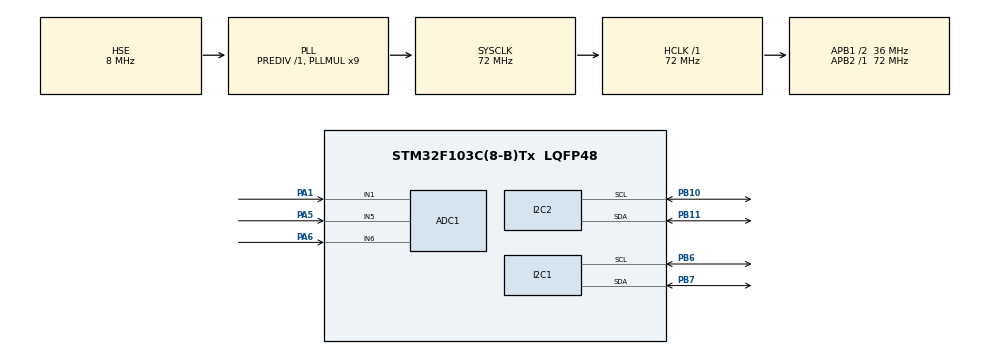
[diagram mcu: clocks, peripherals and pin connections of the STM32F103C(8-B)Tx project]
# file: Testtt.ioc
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ADC1.Channel-4\#ChannelRegularConversion=ADC_CHANNEL_1
ADC1.Channel-5\#ChannelRegularConversion=ADC_CHANNEL_5
ADC1.Channel-6\#ChannelRegularConversion=ADC_CHANNEL_6
ADC1.ContinuousConvMode=ENABLE
ADC1.NbrOfConversion=3
ADC1.NbrOfConversionFlag=1
ADC1.Rank-4\#ChannelRegularConversion=1
ADC1.Rank-5\#ChannelRegularConversion=2
ADC1.Rank-6\#ChannelRegularConversion=3
ADC1.SamplingTime-4\#ChannelRegularConversion=ADC_SAMPLETIME_239CYCLES_5
ADC1.SamplingTime-5\#ChannelRegularConversion=ADC_SAMPLETIME_239CYCLES_5
ADC1.SamplingTime-6\#ChannelRegularConversion=ADC_SAMPLETIME_239CYCLES_5
ADC1.master=1
Dma.ADC1.0.Direction=DMA_PERIPH_TO_MEMORY
Dma.ADC1.0.Instance=DMA1_Channel1
Dma.ADC1.0.MemDataAlignment=DMA_MDATAALIGN_HALFWORD
Dma.ADC1.0.MemInc=DMA_MINC_ENABLE
Dma.ADC1.0.Mode=DMA_CIRCULAR
Dma.ADC1.0.PeriphDataAlignment=DMA_PDATAALIGN_HALFWORD
Dma.ADC1.0.PeriphInc=DMA_PINC_DISABLE
Dma.ADC1.0.Priority=DMA_PRIORITY_LOW
Dma.Request0=ADC1
Mcu.Family=STM32F1
Mcu.Name=STM32F103C(8-B)Tx
Mcu.Package=LQFP48
NVIC.ADC1_2_IRQn=true\:0\:0\:false\:false\:true\:true\:true
NVIC.DMA1_Channel1_IRQn=true\:0\:0\:false\:false\:true\:false\:true
NVIC.I2C1_EV_IRQn=true\:0\:0\:false\:false\:true\:true\:true
NVIC.I2C2_EV_IRQn=true\:0\:0\:false\:false\:true\:true\:true
NVIC.PriorityGroup=NVIC_PRIORITYGROUP_4
NVIC.TIM3_IRQn=true\:0\:0\:false\:false\:true\:true\:true
PA1.Signal=ADCx_IN1
PA13.Mode=Serial_Wire
PA13.Signal=SYS_JTMS-SWDIO
PA14.Mode=Serial_Wire
PA14.Signal=SYS_JTCK-SWCLK
PA5.Signal=ADCx_IN5
PA6.Signal=ADCx_IN6
PB10.Mode=I2C
PB10.Signal=I2C2_SCL
PB11.Mode=I2C
PB11.Signal=I2C2_SDA
PB6.Mode=I2C
PB6.Signal=I2C1_SCL
PB7.Mode=I2C
PB7.Signal=I2C1_SDA
PD0-OSC_IN.Mode=HSE-External-Oscillator
PD0-OSC_IN.Signal=RCC_OSC_IN
PD1-OSC_OUT.Mode=HSE-External-Oscillator
PD1-OSC_OUT.Signal=RCC_OSC_OUT
ProjectManager.HeapSize=0x200
ProjectManager.StackSize=0x400
ProjectManager.TargetToolchain=MDK-ARM V5
RCC.ADCPresc=RCC_ADCPCLK2_DIV6
RCC.AHBFreq_Value=72000000
RCC.APB1CLKDivider=RCC_HCLK_DIV2
RCC.APB1Freq_Value=36000000
RCC.APB1TimFreq_Value=72000000
RCC.APB2Freq_Value=72000000
RCC.APB2TimFreq_Value=72000000
RCC.HCLKFreq_Value=72000000
RCC.PLLMUL=RCC_PLL_MUL9
RCC.PLLSourceVirtual=RCC_PLLSOURCE_HSE
RCC.SYSCLKFreq_VALUE=72000000
RCC.SYSCLKSource=RCC_SYSCLKSOURCE_PLLCLK
RCC.USBFreq_Value=72000000
SH.ADCx_IN1.0=ADC1_IN1,IN1
SH.ADCx_IN5.0=ADC1_IN5,IN5
SH.ADCx_IN6.0=ADC1_IN6,IN6
TIM3.Period=999
TIM3.Prescaler=71
VP_TIM3_VS_ClockSourceINT.Mode=Internal
board=custom

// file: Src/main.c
/* USER CODE BEGIN Header */
/**
  ******************************************************************************
  * @file           : main.c
  * @brief          : Main program body
  ******************************************************************************
  * @attention
  *
  * <h2><center>&copy; Copyright (c) 2020 STMicroelectronics.
  * All rights reserved.</center></h2>
  *
  * This software component is licensed by ST under BSD 3-Clause license,
  * the "License"; You may not use this file except in compliance with the
  * License. You may obtain a copy of the License at:
  *                        opensource.org/licenses/BSD-3-Clause
  *
  ******************************************************************************
  */
/* USER CODE END Header */
#include "main.h"

/* USER CODE BEGIN Includes */
#include "global_define.h"
#include "board.h"
#include "charger_system.h"
/* USER CODE END Includes */

/* USER CODE BEGIN PTD */
  uint32_t haha=0;
uint16_t adcVal[3];
uint16_t _dac_input;
uint8_t pd8_gpio;
Measure_value value;
float current;
/* USER CODE END PTD */

ADC_HandleTypeDef hadc1;
DMA_HandleTypeDef hdma_adc1;

I2C_HandleTypeDef hi2c1;
I2C_HandleTypeDef hi2c2;

TIM_HandleTypeDef htim3;

/* USER CODE BEGIN PV */
float adc_value_1;
float adc_value_2;
float current;
float write_DAC_1( float value)
{
	uint16_t address= 0x60<<1;
	uint8_t data[3];
  data[0]=64;
	uint16_t value_dac= (uint16_t)((value*4095.0f)/3.30f);
	data[1]=value_dac>>4;
	data[2]=value_dac<<4;

	HAL_I2C_Master_Transmit(&hi2c1,address,data,3,500);
	return value;
	}
float write_DAC_2( float value)
{
	uint16_t address= 0x61;
	uint8_t data[3];
  data[0]=64;
	uint16_t value_dac= (uint16_t)((value*4095.0f)/3.30f);
	data[1]=value_dac>>4;
	data[2]=value_dac<<4;

	HAL_I2C_Master_Transmit(&hi2c1,address<<1,data,3,500);
	return value;
	}
void get_value_measure()   // call each 1ms, calculate average value
{

	current=convert_reading_to_charge_current(adcVal[0],1569);

}
void HAL_TIM_PeriodElapsedCallback(TIM_HandleTypeDef *htim)
{
	if (htim->Instance==htim3.Instance) {
			system_state_step();
		current=((adcVal[0]/4095.0f)*3.36*2-2.53)/0.21f;
	}
}
/* USER CODE END PV */

void SystemClock_Config(void);
static void MX_GPIO_Init(void);
static void MX_DMA_Init(void);
static void MX_ADC1_Init(void);
static void MX_I2C1_Init(void);
static void MX_I2C2_Init(void);
static void MX_TIM3_Init(void);

int main(void)
{
  /* USER CODE BEGIN 1 */
//HAL_ADC_Start_DMA(&hadc1, (uint32_t *)adcVal, 3);
//	haha=99;

  /* USER CODE END 1 */

  /* MCU Configuration--------------------------------------------------------*/

  /* Reset of all peripherals, Initializes the Flash interface and the Systick. */
  HAL_Init();

  /* Configure the system clock */
  SystemClock_Config();

  /* Initialize all configured peripherals */
  MX_GPIO_Init();
  MX_DMA_Init();
  MX_ADC1_Init();
  MX_I2C1_Init();
  MX_I2C2_Init();
  MX_TIM3_Init();
  /* USER CODE BEGIN 2 */
		  if (HAL_ADCEx_Calibration_Start(&hadc1) != HAL_OK)
  {
    /* Calibration Error */
    Error_Handler();
  }
  HAL_ADC_Start_DMA(&hadc1, (uint32_t*) &adcVal[0], 3);
	HAL_TIM_Base_Start_IT(&htim3);
	_dac_input = 1345;
	adc_value_1 = write_DAC_1(2.0f);
	adc_value_2 = write_DAC_2(2.0f);

  /* USER CODE END 2 */

  /* Infinite loop */
  while (1)
  {
  }
}

void SystemClock_Config(void)
{
  RCC_OscInitTypeDef RCC_OscInitStruct = {0};
  RCC_ClkInitTypeDef RCC_ClkInitStruct = {0};
  RCC_PeriphCLKInitTypeDef PeriphClkInit = {0};

  /** Initializes the RCC Oscillators according to the specified parameters
  * in the RCC_OscInitTypeDef structure.
  */
  RCC_OscInitStruct.OscillatorType = RCC_OSCILLATORTYPE_HSE;
  RCC_OscInitStruct.HSEState = RCC_HSE_ON;
  RCC_OscInitStruct.HSEPredivValue = RCC_HSE_PREDIV_DIV1;
  RCC_OscInitStruct.HSIState = RCC_HSI_ON;
  RCC_OscInitStruct.PLL.PLLState = RCC_PLL_ON;
  RCC_OscInitStruct.PLL.PLLSource = RCC_PLLSOURCE_HSE;
  RCC_OscInitStruct.PLL.PLLMUL = RCC_PLL_MUL9;
  if (HAL_RCC_OscConfig(&RCC_OscInitStruct) != HAL_OK)
  {
    Error_Handler();
  }
  /** Initializes the CPU, AHB and APB buses clocks
  */
  RCC_ClkInitStruct.ClockType = RCC_CLOCKTYPE_HCLK|RCC_CLOCKTYPE_SYSCLK
                              |RCC_CLOCKTYPE_PCLK1|RCC_CLOCKTYPE_PCLK2;
  RCC_ClkInitStruct.SYSCLKSource = RCC_SYSCLKSOURCE_PLLCLK;
  RCC_ClkInitStruct.AHBCLKDivider = RCC_SYSCLK_DIV1;
  RCC_ClkInitStruct.APB1CLKDivider = RCC_HCLK_DIV2;
  RCC_ClkInitStruct.APB2CLKDivider = RCC_HCLK_DIV1;

  if (HAL_RCC_ClockConfig(&RCC_ClkInitStruct, FLASH_LATENCY_2) != HAL_OK)
  {
    Error_Handler();
  }
  PeriphClkInit.PeriphClockSelection = RCC_PERIPHCLK_ADC;
  PeriphClkInit.AdcClockSelection = RCC_ADCPCLK2_DIV6;
  if (HAL_RCCEx_PeriphCLKConfig(&PeriphClkInit) != HAL_OK)
  {
    Error_Handler();
  }
}

static void MX_ADC1_Init(void)
{

  ADC_ChannelConfTypeDef sConfig = {0};

  /** Common config
  */
  hadc1.Instance = ADC1;
  hadc1.Init.ScanConvMode = ADC_SCAN_ENABLE;
  hadc1.Init.ContinuousConvMode = ENABLE;
  hadc1.Init.DiscontinuousConvMode = DISABLE;
  hadc1.Init.ExternalTrigConv = ADC_SOFTWARE_START;
  hadc1.Init.DataAlign = ADC_DATAALIGN_RIGHT;
  hadc1.Init.NbrOfConversion = 3;
  if (HAL_ADC_Init(&hadc1) != HAL_OK)
  {
    Error_Handler();
  }
  /** Configure Regular Channel
  */
  sConfig.Channel = ADC_CHANNEL_1;
  sConfig.Rank = ADC_REGULAR_RANK_1;
  sConfig.SamplingTime = ADC_SAMPLETIME_239CYCLES_5;
  if (HAL_ADC_ConfigChannel(&hadc1, &sConfig) != HAL_OK)
  {
    Error_Handler();
  }
  /** Configure Regular Channel
  */
  sConfig.Channel = ADC_CHANNEL_5;
  sConfig.Rank = ADC_REGULAR_RANK_2;
  if (HAL_ADC_ConfigChannel(&hadc1, &sConfig) != HAL_OK)
  {
    Error_Handler();
  }
  /** Configure Regular Channel
  */
  sConfig.Channel = ADC_CHANNEL_6;
  sConfig.Rank = ADC_REGULAR_RANK_3;
  if (HAL_ADC_ConfigChannel(&hadc1, &sConfig) != HAL_OK)
  {
    Error_Handler();
  }

}

static void MX_I2C1_Init(void)
{

  hi2c1.Instance = I2C1;
  hi2c1.Init.ClockSpeed = 100000;
  hi2c1.Init.DutyCycle = I2C_DUTYCYCLE_2;
  hi2c1.Init.OwnAddress1 = 0;
  hi2c1.Init.AddressingMode = I2C_ADDRESSINGMODE_7BIT;
  hi2c1.Init.DualAddressMode = I2C_DUALADDRESS_DISABLE;
  hi2c1.Init.OwnAddress2 = 0;
  hi2c1.Init.GeneralCallMode = I2C_GENERALCALL_DISABLE;
  hi2c1.Init.NoStretchMode = I2C_NOSTRETCH_DISABLE;
  if (HAL_I2C_Init(&hi2c1) != HAL_OK)
  {
    Error_Handler();
  }

}

static void MX_I2C2_Init(void)
{

  hi2c2.Instance = I2C2;
  hi2c2.Init.ClockSpeed = 100000;
  hi2c2.Init.DutyCycle = I2C_DUTYCYCLE_2;
  hi2c2.Init.OwnAddress1 = 0;
  hi2c2.Init.AddressingMode = I2C_ADDRESSINGMODE_7BIT;
  hi2c2.Init.DualAddressMode = I2C_DUALADDRESS_DISABLE;
  hi2c2.Init.OwnAddress2 = 0;
  hi2c2.Init.GeneralCallMode = I2C_GENERALCALL_DISABLE;
  hi2c2.Init.NoStretchMode = I2C_NOSTRETCH_DISABLE;
  if (HAL_I2C_Init(&hi2c2) != HAL_OK)
  {
    Error_Handler();
  }

}

static void MX_TIM3_Init(void)
{

  TIM_ClockConfigTypeDef sClockSourceConfig = {0};
  TIM_MasterConfigTypeDef sMasterConfig = {0};

  htim3.Instance = TIM3;
  htim3.Init.Prescaler = 71;
  htim3.Init.CounterMode = TIM_COUNTERMODE_UP;
  htim3.Init.Period = 999;
  htim3.Init.ClockDivision = TIM_CLOCKDIVISION_DIV1;
  htim3.Init.AutoReloadPreload = TIM_AUTORELOAD_PRELOAD_DISABLE;
  if (HAL_TIM_Base_Init(&htim3) != HAL_OK)
  {
    Error_Handler();
  }
  sClockSourceConfig.ClockSource = TIM_CLOCKSOURCE_INTERNAL;
  if (HAL_TIM_ConfigClockSource(&htim3, &sClockSourceConfig) != HAL_OK)
  {
    Error_Handler();
  }
  sMasterConfig.MasterOutputTrigger = TIM_TRGO_RESET;
  sMasterConfig.MasterSlaveMode = TIM_MASTERSLAVEMODE_DISABLE;
  if (HAL_TIMEx_MasterConfigSynchronization(&htim3, &sMasterConfig) != HAL_OK)
  {
    Error_Handler();
  }

}

static void MX_DMA_Init(void)
{

  /* DMA controller clock enable */
  __HAL_RCC_DMA1_CLK_ENABLE();

  /* DMA interrupt init */
  /* DMA1_Channel1_IRQn interrupt configuration */
  HAL_NVIC_SetPriority(DMA1_Channel1_IRQn, 0, 0);
  HAL_NVIC_EnableIRQ(DMA1_Channel1_IRQn);

}

static void MX_GPIO_Init(void)
{
  GPIO_InitTypeDef GPIO_InitStruct = {0};

  /* GPIO Ports Clock Enable */
  __HAL_RCC_GPIOD_CLK_ENABLE();
  __HAL_RCC_GPIOA_CLK_ENABLE();
  __HAL_RCC_GPIOB_CLK_ENABLE();

  /*Configure GPIO pin Output Level */
  HAL_GPIO_WritePin(GPIOB, GPIO_PIN_12, GPIO_PIN_RESET);

  /*Configure GPIO pin : PB12 */
  GPIO_InitStruct.Pin = GPIO_PIN_12;
  GPIO_InitStruct.Mode = GPIO_MODE_OUTPUT_PP;
  GPIO_InitStruct.Pull = GPIO_NOPULL;
  GPIO_InitStruct.Speed = GPIO_SPEED_FREQ_LOW;
  HAL_GPIO_Init(GPIOB, &GPIO_InitStruct);

}

void Error_Handler(void)
{
}

/************************ (C) COPYRIGHT STMicroelectronics *****END OF FILE****/
